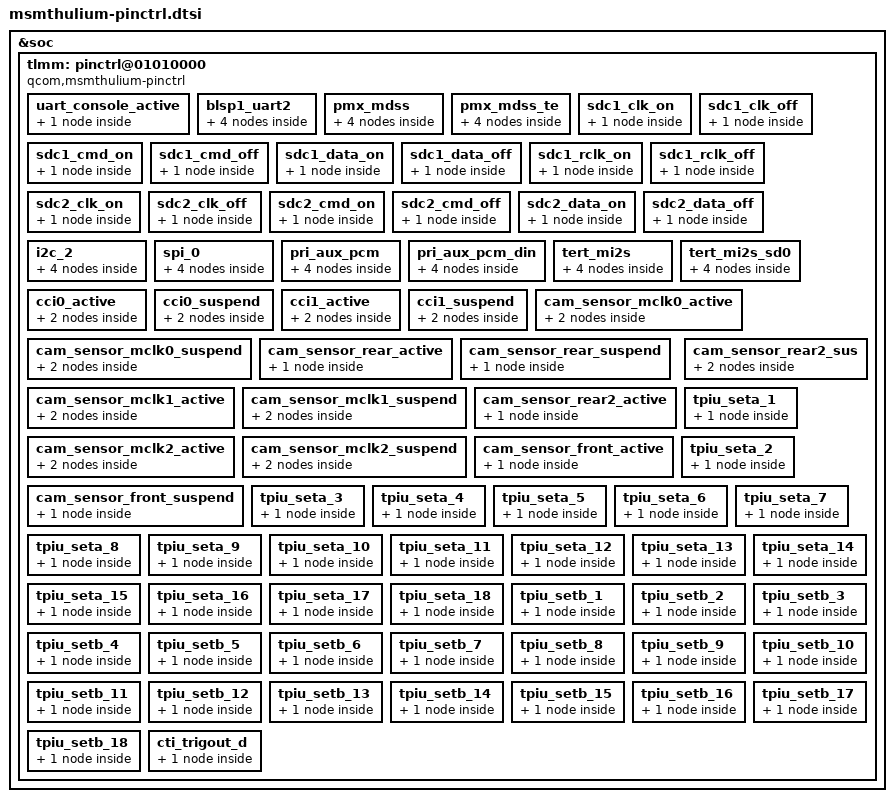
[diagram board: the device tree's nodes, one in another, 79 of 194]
/* Copyright (c) 2014-2015, The Linux Foundation. All rights reserved.
 *
 * This program is free software; you can redistribute it and/or modify
 * it under the terms of the GNU General Public License version 2 and
 * only version 2 as published by the Free Software Foundation.
 *
 * This program is distributed in the hope that it will be useful,
 * but WITHOUT ANY WARRANTY; without even the implied warranty of
 * MERCHANTABILITY or FITNESS FOR A PARTICULAR PURPOSE.  See the
 * GNU General Public License for more details.
 */

&soc {
	tlmm: pinctrl@01010000 {
		compatible = "qcom,msmthulium-pinctrl";
		reg = <0x01010000 0x300000>;
		interrupts = <0 208 0>;
		gpio-controller;
		#gpio-cells = <2>;
		interrupt-controller;
		#interrupt-cells = <2>;

		uart_console_active: uart_console_active {
			pmx-uartconsole {
				pins = "gpio4", "gpio5";
				function = "blsp_uart8";
				drive-strength = <2>;
				bias-disable;
			};
		};

		blsp1_uart2 {
			function = "blsp_uart2";
			bias-disable;

			blsp1_uart2_active: blsp1_uart2_active {
				blsp1_uart2 {
					pins = "gpio41", "gpio42", "gpio43", "gpio44";
					drive-strength = <2>;
				};
			};

			blsp1_uart2_sleep: blsp1_uart2_sleep {
				blsp1_uart2 {
					pins = "gpio41", "gpio42", "gpio43", "gpio44";
					drive-strength = <2>;
				};
			};
		};

		pmx_mdss: pmx_mdss {
			mdss_dsi_active: mdss_dsi_active {
				pmx_mdss {
					pins = "gpio8";
					drive-strength = <8>; /* 8 mA */
					bias-disable = <0>; /* no pull */
					output-high;
				};
			};
			mdss_dsi_suspend: mdss_dsi_suspend {
				pmx_mdss {
					pins = "gpio8";
					drive-strength = <2>; /* 2 mA */
					bias-pull-down; /* pull down */
				};
			};
		};

		pmx_mdss_te: pmx_mdss_te {
			mdss_te_active: mdss_te_active {
				pmx_mdss_te {
					pins = "gpio10";
					drive-strength = <2>; /* 8 mA */
					bias-pull-down = <0>; /* pull down*/
					input-debounce = <0>;
				};
			};
			mdss_te_suspend: mdss_te_suspend {
				pmx_mdss_te {
					pins = "gpio10";
					drive-strength = <2>; /* 2 mA */
					bias-pull-down; /* pull down */
					input-debounce = <0>;
				};
			};
		};

		sdc1_clk_on: sdc1_clk_on {
			pmx_sdc1_clk {
				pins = "sdc1_clk";
				bias-disable;		/* NO pull */
				drive-strength = <16>;	/* 16 MA */
			};
		};

		sdc1_clk_off: sdc1_clk_off {
			pmx_sdc1_clk {
				pins = "sdc1_clk";
				bias-disable;		/* NO pull */
				drive-strength = <2>;	/* 2 MA */
			};
		};

		sdc1_cmd_on: sdc1_cmd_on {
			pmx_sdc1_cmd {
				pins = "sdc1_cmd";
				bias-pull-up;		/* pull up */
				drive-strength = <10>;	/* 10 MA */
			};
		};

		sdc1_cmd_off: sdc1_cmd_off {
			pmx_sdc1_cmd {
				pins = "sdc1_cmd";
				num-grp-pins = <1>;
				bias-pull-up;		/* pull up */
				drive-strength = <2>;	/* 2 MA */
			};
		};

		sdc1_data_on: sdc1_data_on {
			pmx_sdc1_data {
				pins = "sdc1_data";
				bias-pull-up;		/* pull up */
				drive-strength = <10>;	/* 10 MA */
			};
		};

		sdc1_data_off: sdc1_data_off {
			pmx_sdc1_data {
				pins = "sdc1_data";
				bias-pull-up;		/* pull up */
				drive-strength = <2>;	/* 2 MA */
			};
		};

		sdc1_rclk_on: sdc1_rclk_on {
			pmx_sdc1_rclk {
				pins = "sdc1_rclk";
				bias-pull-down;		/* pull down */
			};
		};

		sdc1_rclk_off: sdc1_rclk_off {
			pmx_sdc1_rclk {
				pins = "sdc1_rclk";
				bias-pull-down;		/* pull down */
			};
		};

		sdc2_clk_on: sdc2_clk_on {
			pmx_sdc2_clk {
				pins = "sdc2_clk";
				bias-disable;		/* NO pull */
				drive-strength = <16>;	/* 16 MA */
			};
		};

		sdc2_clk_off: sdc2_clk_off {
			pmx_sdc2_clk {
				pins = "sdc2_clk";
				bias-disable;		/* NO pull */
				drive-strength = <2>;	/* 2 MA */
			};
		};

		sdc2_cmd_on: sdc2_cmd_on {
			pmx_sdc2_cmd {
				pins = "sdc2_cmd";
				bias-pull-up;		/* pull up */
				drive-strength = <10>;	/* 10 MA */
			};
		};

		sdc2_cmd_off: sdc2_cmd_off {
			pmx_sdc2_cmd {
				pins = "sdc2_cmd";
				bias-pull-up;		/* pull up */
				drive-strength = <2>;	/* 2 MA */
			};
		};

		sdc2_data_on: sdc2_data_on {
			pmx_sdc2_data {
				pins = "sdc2_data";
				bias-pull-up;		/* pull up */
				drive-strength = <10>;	/* 10 MA */
			};
		};

		sdc2_data_off: sdc2_data_off {
			pmx_sdc2_data {
				pins = "sdc2_data";
				bias-pull-up;		/* pull up */
				drive-strength = <2>;	/* 2 MA */
			};
		};

		i2c_2 {
			i2c_2_active: i2c_2_active {
				i2c_2 {
					pins = "gpio43", "gpio44";
					function = "blsp_i2c2";
					drive-strength = <2>;
					bias-disable;
				};
			};

			i2c_2_sleep: i2c_2_sleep {
				i2c_2 {
					pins = "gpio43", "gpio44";
					function = "blsp_i2c2";
					drive-strength = <2>;
					bias-disable;
				};
			};
		};

		spi_0 {
			spi_0_active: spi_0_active {
				spi_0 {
					pins = "gpio0", "gpio1", "gpio3";
					function = "blsp_spi1";
					drive-strength = <6>;
					bias-disable;
				};
			};

			spi_0_sleep: spi_0_sleep {
				spi_0 {
					pins = "gpio0", "gpio1", "gpio3";
					function = "blsp_spi1";
					drive-strength = <6>;
					bias-disable;
				};
			};
		};

		pri_aux_pcm {
			pri_aux_pcm_sleep: pri_aux_pcm_sleep {
				pri_aux_pcm {
					pins = "gpio65", "gpio66", "gpio67";
					funcion = "pri_mi2s";
					drive-strength = <2>;   /* 2 mA */
					bias-pull-down;         /* PULL DOWN */
				};
			};
			pri_aux_pcm_active: pri_aux_pcm_active {
				pri_aux_pcm {
					pins = "gpio65", "gpio66", "gpio67";
					funcion = "pri_mi2s";
					drive-strength = <8>;   /* 8 mA */
					bias-disable;           /* NO PULL */
					output-high;
				};
			};
		};

		pri_aux_pcm_din {
			pri_aux_pcm_din_sleep: pri_aux_pcm_din_sleep {
				pri_aux_pcm_din {
					pins = "gpio68";
					funcion = "pri_mi2s";
					drive-strength = <2>;   /* 2 mA */
					bias-pull-down;         /* PULL DOWN */
				};
			};
			pri_aux_pcm_din_active: pri_aux_pcm_din_active {
				pri_aux_pcm_din {
					pins = "gpio68";
					funcion = "pri_mi2s";
					drive-strength = <8>;   /* 8 mA */
					bias-disable;           /* NO PULL */
				};
			};
		};

		tert_mi2s {
			tert_mi2s_sleep: tert_mi2s_sleep {
				tert_mi2s {
					pins = "gpio75", "gpio76";
					funcion = "ter_mi2s";
					drive-strength = <2>;   /* 2 mA */
					bias-pull-down;         /* PULL DOWN */
				};
			};
			tert_mi2s_active: tert_mi2s_active {
				tert_mi2s {
					pins = "gpio75", "gpio76";
					funcion = "ter_mi2s";
					drive-strength = <8>;   /* 8 mA */
					bias-disable;           /* NO PULL */
					output-high;
				};
			};
		};

		tert_mi2s_sd0 {
			tert_mi2s_sd0_sleep: tert_mi2s_sd0_sleep {
				tert_mi2s_sd0 {
					pins = "gpio77";
					funcion = "ter_mi2s";
					drive-strength = <2>;   /* 2 mA */
					bias-pull-down;         /* PULL DOWN */
				};
			};
			tert_mi2s_sd0_active: tert_mi2s_sd0_active {
				tert_mi2s_sd0 {
					pins = "gpio77";
					funcion = "ter_mi2s";
					drive-strength = <8>;   /* 8 mA */
					bias-disable;           /* NO PULL */
				};
			};
		};

		cci0_active: cci0_active {
			cci0_active_mux {
				/* CLK, DATA */
				pins = "gpio17","gpio18"; // Only 2
				function = "cci_i2c";
			};
			cci0_active_cfg {
				pins = "gpio17","gpio18";
				bias-disable; /* No PULL */
				drive-strength = <2>; /* 2 MA */
			};
		};

		cci0_suspend: cci0_suspend {
			cci0_suspend_mux {
				/* CLK, DATA */
				pins = "gpio17","gpio18";
				function = "cci_i2c";
			};
			cci0_suspend_cfg {
				pins = "gpio17","gpio18";
				bias-disable; /* No PULL */
				drive-strength = <2>; /* 2 MA */
			};
		};

		cci1_active: cci1_active {
			cci1_active_mux {
				/* CLK, DATA */
				pins = "gpio19","gpio20";
				function = "cci_i2c";
			};
			cci1_active_cfg {
				pins = "gpio19","gpio20";
				bias-disable; /* No PULL */
				drive-strength = <2>; /* 2 MA */
			};
		};

		cci1_suspend: cci1_suspend {
			cci1_suspend_mux {
				/* CLK, DATA */
				pins = "gpio19","gpio20";
				function = "cci_i2c";
			};
			cci1_suspend_cfg {
				pins = "gpio19","gpio20";
				bias-disable; /* No PULL */
				drive-strength = <2>; /* 2 MA */
			};
		};

		cam_sensor_mclk0_active: cam_sensor_mclk0_active {
			/* MCLK0 */
			mclk0_active_mux {
				/* CLK, DATA */
				pins = "gpio13";
				function = "cam_mclk";
			};
			mclk0_active_cfg {
				pins = "gpio13";
				bias-disable; /* No PULL */
				drive-strength = <2>; /* 2 MA */
			};
		};

		cam_sensor_mclk0_suspend: cam_sensor_mclk0_suspend {
			/* MCLK0 */
			mclk0_suspend_mux {
				/* CLK, DATA */
				pins = "gpio13";
				function = "cam_mclk";
			};
			mclk0_suspend_cfg {
				pins = "gpio13";
				bias-pull-down; /* PULL DOWN */
				drive-strength = <2>; /* 2 MA */
			};
		};

		cam_sensor_rear_active: cam_sensor_rear_active {
			/* RESET, STANDBY */
			cam_rear_active_cfg {
				pins = "gpio30","gpio29";
				bias-disable; /* No PULL */
				drive-strength = <2>; /* 2 MA */
			};
		};

		cam_sensor_rear_suspend: cam_sensor_rear_suspend{
			/* RESET, STANDBY */
			cam_rear_suspend_cfg {
				pins = "gpio30","gpio29";
				bias-disable; /* No PULL */
				drive-strength = <2>; /* 2 MA */
			};
		};

		cam_sensor_mclk1_active: cam_sensor_mclk1_active{
			/* MCLK1 */
			mclk1_active_mux {
				/* CLK, DATA */
				pins = "gpio14";
				function = "cam_mclk";
			};
			mclk1_active_cfg {
				pins = "gpio14";
				bias-disable; /* No PULL */
				drive-strength = <2>; /* 2 MA */
			};
		};

		cam_sensor_mclk1_suspend: cam_sensor_mclk1_suspend {
			/* MCLK1 */
			mclk1_suspend_mux {
				/* CLK, DATA */
				pins = "gpio14";
				function = "cam_mclk";
			};
			mclk1_suspend_cfg {
				pins = "gpio14";
				bias-pull-down; /* PULL DOWN */
				drive-strength = <2>; /* 2 MA */
			};
		};

		cam_sensor_rear2_active: cam_sensor_rear2_active {
			/* RESET, STANDBY */
			cam_rear2_active_cfg {
				pins = "gpio63","gpio62";
				bias-disable; /* No PULL */
				drive-strength = <2>; /* 2 MA */
			};
		};

		cam_sensor_rear2_sus {
			cam_sensor_rear2_suspend: cam_sensor_rear2_suspend{
				/* RESET, STANDBY */
				cam_rear2_suspend_cfg {
					pins = "gpio63","gpio62";
					bias-disable; /* No PULL */
					drive-strength = <2>; /* 2 MA */
				};
			};
		};

		cam_sensor_mclk2_active: cam_sensor_mclk2_active {
			/* MCLK1 */
			mclk2_active_mux {
				/* CLK, DATA */
				pins = "gpio15";
				function = "cam_mclk";
			};
			mclk2_active_cfg {
				pins = "gpio15";
				bias-disable; /* No PULL */
				drive-strength = <2>; /* 2 MA */
			};
		};

		cam_sensor_mclk2_suspend: cam_sensor_mclk2_suspend{
			/* MCLK1 */
			mclk1_suspend_mux {
				/* CLK, DATA */
				pins = "gpio15";
				function = "cam_mclk";
			};
			mclk2_suspend_cfg {
				pins = "gpio15";
				bias-pull-down; /* PULL DOWN */
				drive-strength = <2>; /* 2 MA */
			};
		};

		cam_sensor_front_active: cam_sensor_front_active{
			/* RESET, STANDBY */
			cam_front_active_cfg {
				pins = "gpio23","gpio26";
				bias-disable; /* No PULL */
				drive-strength = <2>; /* 2 MA */
			};
		};

		cam_sensor_front_suspend: cam_sensor_front_suspend{
			/* RESET, STANDBY */
			cam_front_suspend_cfg {
				pins = "gpio23","gpio26";
				bias-disable; /* No PULL */
				drive-strength = <2>; /* 2 MA */
			};
		};

		/* CoreSight */
		tpiu_seta_1 {
			pins = "gpio27";
			function = "qdss_tracectl_a";
			label = "tpiu-seta-1";
			seta_1: seta {
				drive-strength = <16>;
				bias-disable;
			};
		};

		tpiu_seta_2 {
			pins = "gpio28";
			function = "qdss_tracectl_a";
			label = "tpiu-seta-2";
			seta_2: seta {
				drive-strength = <16>;
				bias-disable;
			};
		};

		tpiu_seta_3 {
			pins = "gpio53";
			function = "qdss_tracedata_a";
			label = "tpiu-seta-3";
			seta_3: seta {
				drive-strength = <16>;
				bias-disable;
			};
		};

		tpiu_seta_4 {
			pins = "gpio54";
			function = "qdss_tracedata_a";
			label = "tpiu-seta-4";
			seta_4: seta {
				drive-strength = <16>;
				bias-disable;
			};
		};

		tpiu_seta_5 {
			pins = "gpio63";
			function = "qdss_tracedata_a";
			label = "tpiu-seta-5";
			seta_5: seta {
				drive-strength = <16>;
				bias-disable;
			};
		};

		tpiu_seta_6 {
			pins = "gpio64";
			function = "qdss_tracedata_a";
			label = "tpiu-seta-6";
			seta_6: seta {
				drive-strength = <16>;
				bias-disable;
			};
		};

		tpiu_seta_7 {
			pins = "gpio65";
			function = "qdss_tracedata_a";
			label = "tpiu-seta-7";
			seta_7: seta {
				drive-strength = <16>;
				bias-disable;
			};
		};

		tpiu_seta_8 {
			pins = "gpio66";
			function = "qdss_tracedata_a";
			label = "tpiu-seta-8";
			seta_8: seta {
				drive-strength = <16>;
				bias-disable;
			};
		};

		tpiu_seta_9 {
			pins = "gpio67";
			function = "qdss_tracedata_a";
			label = "tpiu-seta-9";
			seta_9: seta {
				drive-strength = <16>;
				bias-disable;
			};
		};

		tpiu_seta_10 {
			pins = "gpio74";
			function = "qdss_tracedata_a";
			label = "tpiu-seta-10";
			seta_10: seta {
				drive-strength = <16>;
				bias-disable;
			};
		};

		tpiu_seta_11 {
			pins = "gpio75";
			function = "qdss_tracedata_a";
			label = "tpiu-seta-11";
			seta_11: seta {
				drive-strength = <16>;
				bias-disable;
			};
		};

		tpiu_seta_12 {
			pins = "gpio76";
			function = "qdss_tracedata_a";
			label = "tpiu-seta-12";
			seta_12: seta {
				drive-strength = <16>;
				bias-disable;
			};
		};

		tpiu_seta_13 {
			pins = "gpio77";
			function = "qdss_tracedata_a";
			label = "tpiu-seta-13";
			seta_13: seta {
				drive-strength = <16>;
				bias-disable;
			};
		};

		tpiu_seta_14 {
			pins = "gpio85";
			function = "qdss_tracedata_a";
			label = "tpiu-seta-14";
			seta_14: seta {
				drive-strength = <16>;
				bias-disable;
			};
		};

		tpiu_seta_15 {
			pins = "gpio86";
			function = "qdss_tracedata_a";
			label = "tpiu-seta-15";
			seta_15: seta {
				drive-strength = <16>;
				bias-disable;
			};
		};

		tpiu_seta_16 {
			pins = "gpio87";
			function = "qdss_tracedata_a";
			label = "tpiu-seta-16";
			seta_16: seta {
				drive-strength = <16>;
				bias-disable;
			};
		};

		tpiu_seta_17 {
			pins = "gpio89";
			function = "qdss_tracedata_a";
			label = "tpiu-seta-17";
			seta_17: seta {
				drive-strength = <16>;
				bias-disable;
			};
		};

		tpiu_seta_18 {
			pins = "gpio90";
			function = "qdss_tracedata_a";
			label = "tpiu-seta-18";
			seta_18: seta {
				drive-strength = <16>;
				bias-disable;
			};
		};

		tpiu_setb_1 {
			pins = "gpio13";
			function = "qdss_tracedata_b";
			label = "tpiu-setb-1";
			setb_1: setb {
				drive-strength = <16>;
				bias-disable;
			};
		};

		tpiu_setb_2 {
			pins = "gpio14";
			function = "qdss_tracedata_b";
			label = "tpiu-setb-2";
			setb_2: setb {
				drive-strength = <16>;
				bias-disable;
			};
		};

		tpiu_setb_3 {
			pins = "gpio15";
			function = "qdss_tracedata_b";
			label = "tpiu-setb-3";
			setb_3: setb {
				drive-strength = <16>;
				bias-disable;
			};
		};

		tpiu_setb_4 {
			pins = "gpio16";
			function = "qdss_tracedata_b";
			label = "tpiu-setb-4";
			setb_4: setb {
				drive-strength = <16>;
				bias-disable;
			};
		};

		tpiu_setb_5 {
			pins = "gpio17";
			function = "qdss_tracedata_b";
			label = "tpiu-setb-5";
			setb_5: setb {
				drive-strength = <16>;
				bias-disable;
			};
		};

		tpiu_setb_6 {
			pins = "gpio18";
			function = "qdss_tracedata_b";
			label = "tpiu-setb-6";
			setb_6: setb {
				drive-strength = <16>;
				bias-disable;
			};
		};

		tpiu_setb_7 {
			pins = "gpio19";
			function = "qdss_tracedata_b";
			label = "tpiu-setb-7";
			setb_7: setb {
				drive-strength = <16>;
				bias-disable;
			};
		};

		tpiu_setb_8 {
			pins = "gpio21";
			function = "qdss_tracedata_b";
			label = "tpiu-setb-8";
			setb_8: setb {
				drive-strength = <16>;
				bias-disable;
			};
		};

		tpiu_setb_9 {
			pins = "gpio22";
			function = "qdss_tracedata_b";
			label = "tpiu-setb-9";
			setb_9: setb {
				drive-strength = <16>;
				bias-disable;
			};
		};

		tpiu_setb_10 {
			pins = "gpio23";
			function = "qdss_tracedata_b";
			label = "tpiu-setb-10";
			setb_10: setb {
				drive-strength = <16>;
				bias-disable;
			};
		};

		tpiu_setb_11 {
			pins = "gpio26";
			function = "qdss_tracedata_b";
			label = "tpiu-setb-11";
			setb_11: setb {
				drive-strength = <16>;
				bias-disable;
			};
		};

		tpiu_setb_12 {
			pins = "gpio29";
			function = "qdss_tracedata_b";
			label = "tpiu-setb-12";
			setb_12: setb {
				drive-strength = <16>;
				bias-disable;
			};
		};

		tpiu_setb_13 {
			pins = "gpio57";
			function = "qdss_tracedata_b";
			label = "tpiu-setb-13";
			setb_13: setb {
				drive-strength = <16>;
				bias-disable;
			};
		};

		tpiu_setb_14 {
			pins = "gpio58";
			function = "qdss_tracedata_b";
			label = "tpiu-setb-14";
			setb_14: setb {
				drive-strength = <16>;
				bias-disable;
			};
		};

		tpiu_setb_15 {
			pins = "gpio91";
			function = "qdss_traceclk_b";
			label = "tpiu-setb-15";
			setb_15: setb {
				drive-strength = <16>;
				bias-disable;
			};
		};

		tpiu_setb_16 {
			pins = "gpio92";
			function = "qdss_tracedata_b";
			label = "tpiu-setb-16";
			setb_16: setb {
				drive-strength = <16>;
				bias-disable;
			};
		};

		tpiu_setb_17 {
			pins = "gpio93";
			function = "qdss_tracedata_b";
			label = "tpiu-setb-17";
			setb_17: setb {
				drive-strength = <16>;
				bias-disable;
			};
		};

		tpiu_setb_18 {
			pins = "gpio94";
			function = "qdss_tracectl_b";
			label = "tpiu-setb-18";
			setb_18: setb {
				drive-strength = <16>;
				bias-disable;
			};
		};

		cti_trigout_d {
			pins = "gpio100";
			function = "qdss_cti";
			label = "cti-trigout-d";
			trigout_d: trigout_d {
				drive-strength = <2>;
				bias-disable;
			};
		};
	};
};
